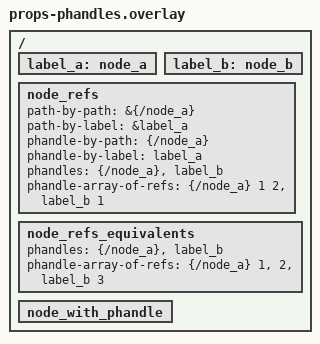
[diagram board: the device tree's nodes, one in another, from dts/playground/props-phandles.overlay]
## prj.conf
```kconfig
# Empty/unused.
```

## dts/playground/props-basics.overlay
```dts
/* The DTS file version is **not** specified in an overlay file! */
// /dts-v1/;

/ {
  aliases {
    // `aliases` is a standard child-node of the root node defined by the DTSpec.
    // Aliases cannot be used as a references in the devicetree itself, but are
    // used within the application as an alternative name for a node.
    alias-by-label = &label_equivalent;
    alias-by-path = &{/node_with_equivalent_arrays};
    alias-as-string = "/node_with_equivalent_arrays";
    // The DTS generator or compiler checks properties and makes sure that the given
    // values are valid paths. E.g., the following would not compile since the node
    // "invalid" does not exist:
    // alias-foo = "/invalid";
  };

  chosen {
    // `chosen` is yet another standard child-node of the root node defined by the DTSpec.
    // It describes parameters "chosen" or specified by the application. Such parameters
    // can be paths to nodes, e.g., for `zephyr,parameters` such as `zephyr,console`, but
    // also any other property and value.
    chosen-by-label = &label_equivalent;
    chosen-by-path = &{/node_with_equivalent_arrays};
    chosen-as-string = "/node_with_equivalent_arrays";
    // `chosen` properties can have any valid type, but in Zephyr they are typically only
    // used to reference nodes (see also, the DT_CHOSEN macro). Other options are more
    // commonly specified using Kconfig.
    chosen-foo = "bar";
    chosen-bar = <0xF00>;
  };

  node_with_props {
    existent-boolean;
    int = <1>;
    array = <1 2 3>;
    uint8-array = [ 12 34  ];
    string = "foo";
    string-array = "foo", "bar", "baz";
  };
  label_equivalent: node_with_equivalent_arrays {
    // No spaces needed for uint8-array values.
    uint8-array = [ 12 34  ];
    // Alternative syntax for arrays.
    array = <1>, <2>, <3>;
    int = <1>;
  };
};

// It is not possible to refer to a node via its alias - aliases are just properties!
// &alias-by-label {... };

// It is possible to "extend" and overwrite (non-const) properties of a node using
// its full path or its label. This overwrites the `int` property's value with _2_
// for the existing node "/node_with_equivalent_arrays".
&{/node_with_equivalent_arrays} {
  int = <2>;
};
// The same can be done using labels.
&label_equivalent {
  string = "bar";
};
```

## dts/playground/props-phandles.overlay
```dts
/* The DTS file version is **not** specified in an overlay file! */
// /dts-v1/;

/ {
  label_a: node_a {
    // The value assignment for the cells is redundant in Zephyr, since
    // the binding already specifies all names and thus the size.
    #phandle-array-of-ref-cells = <2>;
  };
  label_b: node_b {
    #phandle-array-of-ref-cells = <1>;
  };

  node_refs {
    // Properties of type `path`
    path-by-path = &{/node_a};
    path-by-label = &label_a;

    // Properties of type `phandle`
    phandle-by-path = <&{/node_a}>;
    phandle-by-label = <&label_a>;

    // Array of phandle, type `phandles`
    phandles = <&{/node_a} &label_b>;
    // Array of phandles _with metadata_, type `phandle-array`
    phandle-array-of-refs = <&{/node_a} 1 2 &label_b 1>;
  };

  node_refs_equivalents {
    phandles = <&{/node_a}>, <&label_b>;
    phandle-array-of-refs = <&{/node_a} 1>, <2 &label_b 3>;
  };

  node_with_phandle {
    // It is allowed to explicitly provide the phandle's value, but the
    // DTS generator does this for us.
    phandle = <0xC0FFEE>;
  };
};
```

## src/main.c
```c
/** \file main.c */

#include <zephyr/kernel.h>

#define SLEEP_TIME_MS 100U

int main(void)
{
    printk("Message in a bottle.\n");

    while (1)
    {
        k_msleep(SLEEP_TIME_MS);
    }
}
```
